VERSION ""

NS_ :

BS_:
BU_: UserApplication MCM
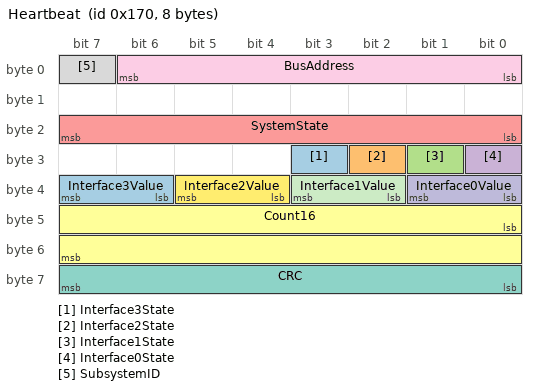
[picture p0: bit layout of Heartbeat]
BO_ 368 Heartbeat: 8 MCM
   SG_ Interface3State : 27|1@1+ (1,0) [0|0] "" Vector__XXX
   SG_ Interface2State : 26|1@1+ (1,0) [0|0] "" Vector__XXX
   SG_ Interface1State : 25|1@1+ (1,0) [0|0] "" Vector__XXX
   SG_ Interface0State : 24|1@1+ (1,0) [0|0] "" Vector__XXX
   SG_ SystemState : 16|8@1+ (1,0) [0|0] "" Vector__XXX
   SG_ Count16 : 40|16@1+ (1,0) [0|0] "" Vector__XXX
   SG_ CRC : 56|8@1+ (1,0) [0|0] "" Vector__XXX
   SG_ SubsystemID : 7|1@1+ (1,0) [0|0] "" Vector__XXX
   SG_ BusAddress : 0|7@1+ (1,0) [0|0] "" Vector__XXX
   SG_ Interface0Value : 32|2@1+ (1,0) [0|0] "" Vector__XXX
   SG_ Interface1Value : 34|2@1+ (1,0) [0|0] "" Vector__XXX
   SG_ Interface2Value : 36|2@1+ (1,0) [0|0] "" Vector__XXX
   SG_ Interface3Value : 38|2@1+ (1,0) [0|0] "" Vector__XXX

BA_DEF_ SG_ "SigType" ENUM "No","Yes","Default","Range","RangeSigned","ASCII","Discrete","Control","ReferencePGN","DTC","StringDelimiter","StringLength","StringLengthControl","MessageCounter","MessageChecksum";
BA_DEF_ SG_ "GenSigEVName" STRING ;
BA_DEF_ SG_ "GenSigILSupport" ENUM "No","Yes","Default","Range","RangeSigned","ASCII","Discrete","Control","ReferencePGN","DTC","StringDelimiter","StringLength","StringLengthControl","MessageCounter","MessageChecksum","No","Yes";
BA_DEF_ SG_ "GenSigSendType" ENUM "No","Yes","Default","Range","RangeSigned","ASCII","Discrete","Control","ReferencePGN","DTC","StringDelimiter","StringLength","StringLengthControl","MessageCounter","MessageChecksum","No","Yes","Cyclic","OnWrite","OnWriteWithRepetition","OnChange","OnChangeWithRepetition","IfActive","IfActiveWithRepetition","NoSigSendType";
BA_DEF_ BO_ "GenMsgILSupport" ENUM "No","Yes","Default","Range","RangeSigned","ASCII","Discrete","Control","ReferencePGN","DTC","StringDelimiter","StringLength","StringLengthControl","MessageCounter","MessageChecksum","No","Yes","Cyclic","OnWrite","OnWriteWithRepetition","OnChange","OnChangeWithRepetition","IfActive","IfActiveWithRepetition","NoSigSendType","No","Yes";
BA_DEF_ BU_ "NmStationAddress" INT 0 255;
BA_DEF_ BO_ "GenMsgSendType" ENUM "No","Yes","Default","Range","RangeSigned","ASCII","Discrete","Control","ReferencePGN","DTC","StringDelimiter","StringLength","StringLengthControl","MessageCounter","MessageChecksum","No","Yes","Cyclic","OnWrite","OnWriteWithRepetition","OnChange","OnChangeWithRepetition","IfActive","IfActiveWithRepetition","NoSigSendType","No","Yes","cyclic","NotUsed","IfActive","NotUsed","NotUsed","NotUsed","NotUsed","NotUsed","noMsgSendType";
BA_DEF_ BO_ "GenMsgRequestable" INT 0 1;
BA_DEF_ "BusType" STRING ;
BA_DEF_ "ProtocolType" STRING ;
BA_DEF_ BO_ "VFrameFormat" ENUM "No","Yes","Default","Range","RangeSigned","ASCII","Discrete","Control","ReferencePGN","DTC","StringDelimiter","StringLength","StringLengthControl","MessageCounter","MessageChecksum","No","Yes","Cyclic","OnWrite","OnWriteWithRepetition","OnChange","OnChangeWithRepetition","IfActive","IfActiveWithRepetition","NoSigSendType","No","Yes","cyclic","NotUsed","IfActive","NotUsed","NotUsed","NotUsed","NotUsed","NotUsed","noMsgSendType","StandardCAN","ExtendedCAN","reserved","J1939PG";
BA_DEF_ BO_ "GenMsgBackgroundColor" STRING ;
BA_DEF_ BO_ "GenMsgForegroundColor" STRING ;
BA_DEF_ BO_ "filterlabeling" INT 0 0;
BA_ "NmStationAddress" BU_ UserApplication 241;
BA_ "NmStationAddress" BU_ MCM 0;
BA_ "VFrameFormat" BO_ 368 0;
BA_DEF_DEF_ "SigType" "Default";
BA_DEF_DEF_ "GenSigEVName" "Env";
BA_DEF_DEF_ "GenSigILSupport" "Yes";
BA_DEF_DEF_ "GenSigSendType" "NoSigSendType";
BA_DEF_DEF_ "GenMsgILSupport" "Yes";
BA_DEF_DEF_ "NmStationAddress" 254;
BA_DEF_DEF_ "GenMsgSendType" "noMsgSendType";
BA_DEF_DEF_ "GenMsgRequestable" 1;
BA_DEF_DEF_ "BusType" "CAN";
BA_DEF_DEF_ "ProtocolType" "J1939";
BA_DEF_DEF_ "VFrameFormat" "J1939PG";
BA_DEF_DEF_ "GenMsgBackgroundColor" "#ffffff";
BA_DEF_DEF_ "GenMsgForegroundColor" "#000000";
BA_DEF_DEF_ "filterlabeling" 1;
VAL_ 368 Interface3State 1 "MCM Control" 0 "Human Control";
VAL_ 368 Interface2State 1 "MCM Control" 0 "Human Control";
VAL_ 368 Interface1State 1 "MCM Control" 0 "Human Control";
VAL_ 368 Interface0State 1 "MCM Control" 0 "Human Control";
VAL_ 368 SystemState 254 "Fail Hard" 253 "Human Override" 242 "Fail Operational 2" 241 "Fail Operational 1" 1 "MCM Control" 0 "Human Control";
VAL_ 368 Interface0Value 1 "Pull_Down" 0 "HiZ" 2 "Pull_Up";
VAL_ 368 Interface1Value 1 "Pull_Down" 0 "HiZ" 2 "Pull_Up";
VAL_ 368 Interface2Value 1 "Pull_Down" 0 "HiZ" 2 "Pull_Up";
VAL_ 368 Interface3Value 1 "Pull_Down" 0 "HiZ" 2 "Pull_Up";
